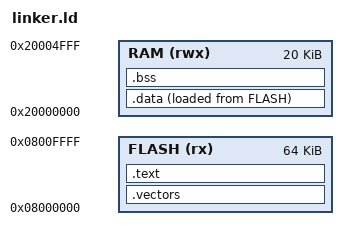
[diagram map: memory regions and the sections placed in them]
MEMORY
{
    FLASH (rx)  : ORIGIN = 0x08000000, LENGTH = 64K
    RAM   (rwx) : ORIGIN = 0x20000000, LENGTH = 20K
}

SECTIONS
{
    /* Vector table must be first in FLASH */
    .vectors :
    {
        . = ALIGN(4);
        KEEP(*(.vectors))
        . = ALIGN(4);
    } > FLASH

    /* Code and read-only data */
    .text :
    {
        . = ALIGN(4);
        *(.text*)
        *(.rodata*)
        . = ALIGN(4);

        _etext = .;
    } > FLASH

    /* Initialized data
       LMA = FLASH
       VMA = RAM
    */
    .data :
    {
        . = ALIGN(4);

        _sdata = .;

        *(.data*)

        . = ALIGN(4);

        _edata = .;
    } > RAM AT > FLASH

    /* Uninitialized data */
    .bss :
    {
        . = ALIGN(4);

        _sbss = .;

        *(.bss*)
        *(COMMON)

        . = ALIGN(4);

        _ebss = .;
    } > RAM
}
